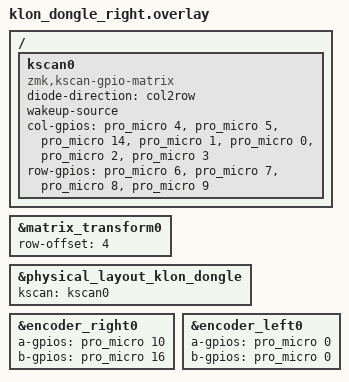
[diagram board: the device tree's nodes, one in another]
#include "klon_dongle.dtsi"

/ {
    kscan0: kscan0 {
        compatible = "zmk,kscan-gpio-matrix";
                diode-direction = "col2row";
        wakeup-source;

        col-gpios
            = <&pro_micro 4 GPIO_ACTIVE_HIGH>
            , <&pro_micro 5 GPIO_ACTIVE_HIGH>
            , <&pro_micro 14 GPIO_ACTIVE_HIGH>
            , <&pro_micro 1 GPIO_ACTIVE_HIGH>
            , <&pro_micro 0 GPIO_ACTIVE_HIGH>
            , <&pro_micro 2 GPIO_ACTIVE_HIGH>
            , <&pro_micro 3 GPIO_ACTIVE_HIGH>
            ;

        row-gpios
            = <&pro_micro 6 (GPIO_ACTIVE_HIGH | GPIO_PULL_DOWN)>
            , <&pro_micro 7 (GPIO_ACTIVE_HIGH | GPIO_PULL_DOWN)>
            , <&pro_micro 8 (GPIO_ACTIVE_HIGH | GPIO_PULL_DOWN)>
            , <&pro_micro 9 (GPIO_ACTIVE_HIGH | GPIO_PULL_DOWN)>
            ;
    };
};

&matrix_transform0 {
    row-offset = <4>;
};

&physical_layout_klon_dongle {
    kscan = <&kscan0>;
};

&encoder_right0 {
    a-gpios = <&pro_micro 10 (GPIO_ACTIVE_HIGH | GPIO_PULL_UP)>;
    b-gpios = <&pro_micro 16 (GPIO_ACTIVE_HIGH | GPIO_PULL_UP)>;
    status = "okay";
};

// Assigning dummy pins to other part's encoders
// just to satisfy the devicetree requirements.
// No code will be compiled for these disabled encoders.
&encoder_left0 {
    a-gpios = <&pro_micro 0 (GPIO_ACTIVE_HIGH | GPIO_PULL_UP)>;
    b-gpios = <&pro_micro 0 (GPIO_ACTIVE_HIGH | GPIO_PULL_UP)>;
};

